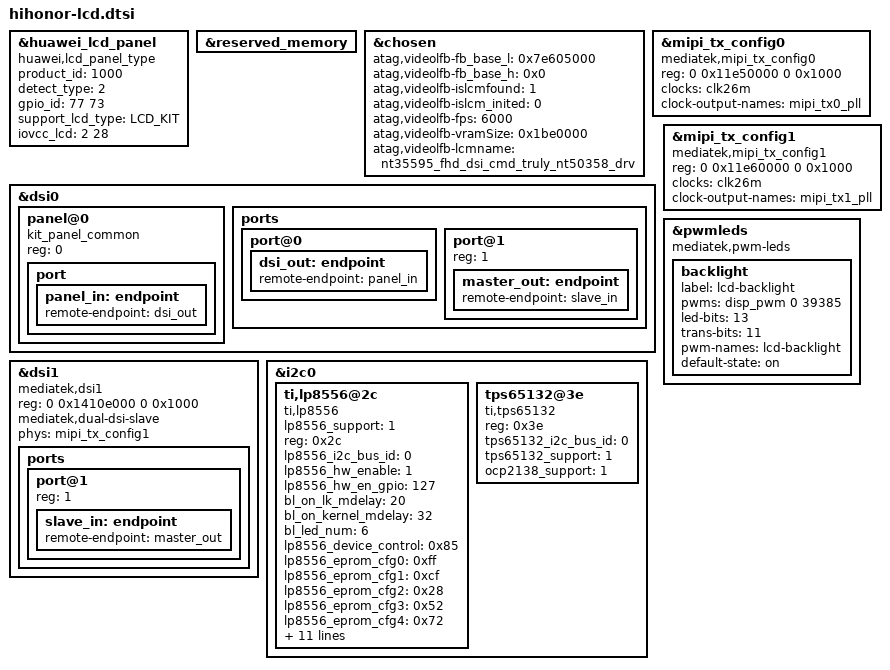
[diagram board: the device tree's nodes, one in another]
#include "mediatek/lcdkit3.0/brt/devkit_lcd_kit.dtsi"

&huawei_lcd_panel {
		compatible = "huawei,lcd_panel_type";
		product_id = <1000>;
		detect_type = <2>; /*0:DETECT_GPIOID  1:DETECT_CHIPID  2:DETECT_LCD_TYPE */
		gpio_id = <77 73>; /*ID0 ID1*/
		support_lcd_type = "LCD_KIT";
		iovcc_lcd = <2 28>;
};

&reserved_memory {
};


/* chosen */
&chosen {
	atag,videolfb-fb_base_l = <0x7e605000>;
	atag,videolfb-fb_base_h = <0x0>;
	atag,videolfb-islcmfound = <1>;
	atag,videolfb-islcm_inited = <0>;
	atag,videolfb-fps= <6000>;
	atag,videolfb-vramSize= <0x1be0000>;
	atag,videolfb-lcmname=
		"nt35595_fhd_dsi_cmd_truly_nt50358_drv";
};

&mipi_tx_config0 {
    compatible = "mediatek,mipi_tx_config0",
            "mediatek,mt6885-mipi-tx-cphy";
    reg = <0 0x11e50000 0 0x1000>;
    clocks = <&clk26m>;
    #clock-cells = <0>;
    #phy-cells = <0>;
    clock-output-names = "mipi_tx0_pll";
};

&dsi0 {
	status = "okay";
	#address-cells = <1>;
	#size-cells = <0>;
	panel@0 {
		compatible = "kit_panel_common";
		reg = <0>;
		port {
			panel_in: endpoint {
				remote-endpoint = <&dsi_out>;
			};
		};
	};
	ports {
		port@0 {
			dsi_out: endpoint {
				remote-endpoint = <&panel_in>;
			};
		};

		port@1 {
			reg = <1>;
			master_out: endpoint {
				remote-endpoint = <&slave_in>;
			};
		};
	};
};

&dsi1 {
	status = "okay";
	compatible = "mediatek,dsi1",
		"mediatek,mt6885-dsi";
	reg = <0 0x1410e000 0 0x1000>;
	mediatek,dual-dsi-slave;
	phys = <&mipi_tx_config1>;
	phy-names = "dphy";
	ports {
		port@1 {
			reg = <1>;
			slave_in: endpoint {
				remote-endpoint = <&master_out>;
			};
		};
	};
};

&mipi_tx_config1 {
	status = "okay";
	compatible = "mediatek,mipi_tx_config1",
		     "mediatek,mt6885-mipi-tx-cphy";
	reg = <0 0x11e60000 0 0x1000>;
	clocks = <&clk26m>;
	#clock-cells = <0>;
	#phy-cells = <0>;
	clock-output-names = "mipi_tx1_pll";
};


&pwmleds {
	compatible = "mediatek,pwm-leds";

	backlight {
		label = "lcd-backlight";
		pwms = <&disp_pwm 0 39385>;
		led-bits = <13>;
		trans-bits = <11>;
		pwm-names = "lcd-backlight";
		default-state = "on";
	};
};

&i2c0{

	ti,lp8556@2c{
		compatible = "ti,lp8556";
		lp8556_support = <1>;
		reg = <0x2c>;
		lp8556_i2c_bus_id = <0>;
		lp8556_hw_enable = <1>;
		lp8556_hw_en_gpio = <127>;
		bl_on_lk_mdelay = <20>;
		bl_on_kernel_mdelay = <32>;
		bl_led_num = <6>;
		lp8556_device_control = <0x85>;
		lp8556_eprom_cfg0 = <0xff>;
		lp8556_eprom_cfg1 = <0xcf>;
		lp8556_eprom_cfg2 = <0x28>;
		lp8556_eprom_cfg3 = <0x52>;
		lp8556_eprom_cfg4 = <0x72>;
		lp8556_eprom_cfg5 = <0x00>;
		lp8556_eprom_cfg6 = <0x80>;
		lp8556_eprom_cfg7 = <0xf7>;
		lp8556_eprom_cfg9 = <0x80>;
		lp8556_eprom_cfgA = <0x0f>;
		lp8556_eprom_cfgE = <0x0e>;
		lp8556_eprom_cfg9E = <0x22>;
		lp8556_led_enable = <0x3f>;
		lp8556_eprom_cfg98 = <0x00>;
		lp8556_level_lsb = <0x10>;
		lp8556_level_msb = <0x11>;
	};

	tps65132@3e {
		compatible = "ti,tps65132";
		reg = <0x3e>;
		tps65132_i2c_bus_id = <0>;
		tps65132_support = <1>;
		ocp2138_support = <1>;
		status = "ok";
	};
};
